AUTOSAR XML (schema 4.0)
package /S07ADMI/If
  sender receiver interface AdminCmd
    data val
  sender receiver interface StarterCmd
    data val
package /S07ADMI/Swc
  application sw component type AdminPanel
    provide port panelToFleetOut: provided-interface=AdminCmd
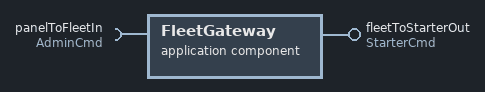
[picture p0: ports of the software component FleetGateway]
  application sw component type FleetGateway
    provide port fleetToStarterOut: provided-interface=StarterCmd
    require port panelToFleetIn: required-interface=AdminCmd
  application sw component type StarterCtrl
    require port fleetToStarterIn: required-interface=StarterCmd
  composition sw component type Root
    component panel: type=AdminPanel
    component fleet: type=FleetGateway
    component starter: type=StarterCtrl
    connect panel.panelToFleetOut -> fleet.panelToFleetIn
    connect fleet.fleetToStarterOut -> starter.fleetToStarterIn
package /S07ADMI/Comm
  pdu panelToFleetIPdu
    signal panelToFleetISig: system signal panelToFleetSSig
  secured i pdu panelToFleetSecuredIPdu: auth-info-tx-length=32, freshness-value-id=1, freshness-value-length=8, payload=panelToFleetIPdu
  pdu fleetToStarterIPdu
    signal fleetToStarterISig: system signal fleetToStarterSSig
  secured i pdu fleetToStarterSecuredIPdu: auth-info-tx-length=32, freshness-value-id=1, freshness-value-length=8, payload=fleetToStarterIPdu
package /S07ADMI/Topology
  ecu instance GatewayEcu
  ecu instance PowertrainEcu
  ecu instance TelematicsEcu
  system Veh
    root-software-compositions:
      root sw composition prototype Root: software-composition=Root
    system mapping Map
      data-mappings:
        data-element=Root.panelToFleetOut.val, system-signal=panelToFleetSSig
        data-element=Root.fleetToStarterOut.val, system-signal=fleetToStarterSSig
      sw-mappings:
        swc to ecu mapping ToGatewayEcu: component=fleet, ecu-instance=GatewayEcu
        swc to ecu mapping ToPowertrainEcu: component=starter, ecu-instance=PowertrainEcu
        swc to ecu mapping ToTelematicsEcu: component=panel, ecu-instance=TelematicsEcu
